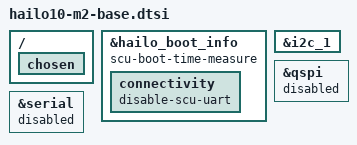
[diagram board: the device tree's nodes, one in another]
// SPDX-License-Identifier: GPL-2.0
/*
 * base dts file for Hailo10-M.2 board.
 *
 * Copyright (c) 2019-2024 Hailo Technologies Ltd. All rights reserved.
 */

#include "hailo10-base.dtsi"
#include "hailo15_ddr_configuration.dtsi"

&hailo_boot_info {
    scu-boot-time-measure;
    connectivity {
        disable-scu-uart;
    };
};

&i2c_1 {
    status = "okay";
};

&qspi {
    status = "disabled";
};

&serial {
    status = "disabled";
};
/ {
    chosen {
        /delete-property/ stdout-path;
    };
};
